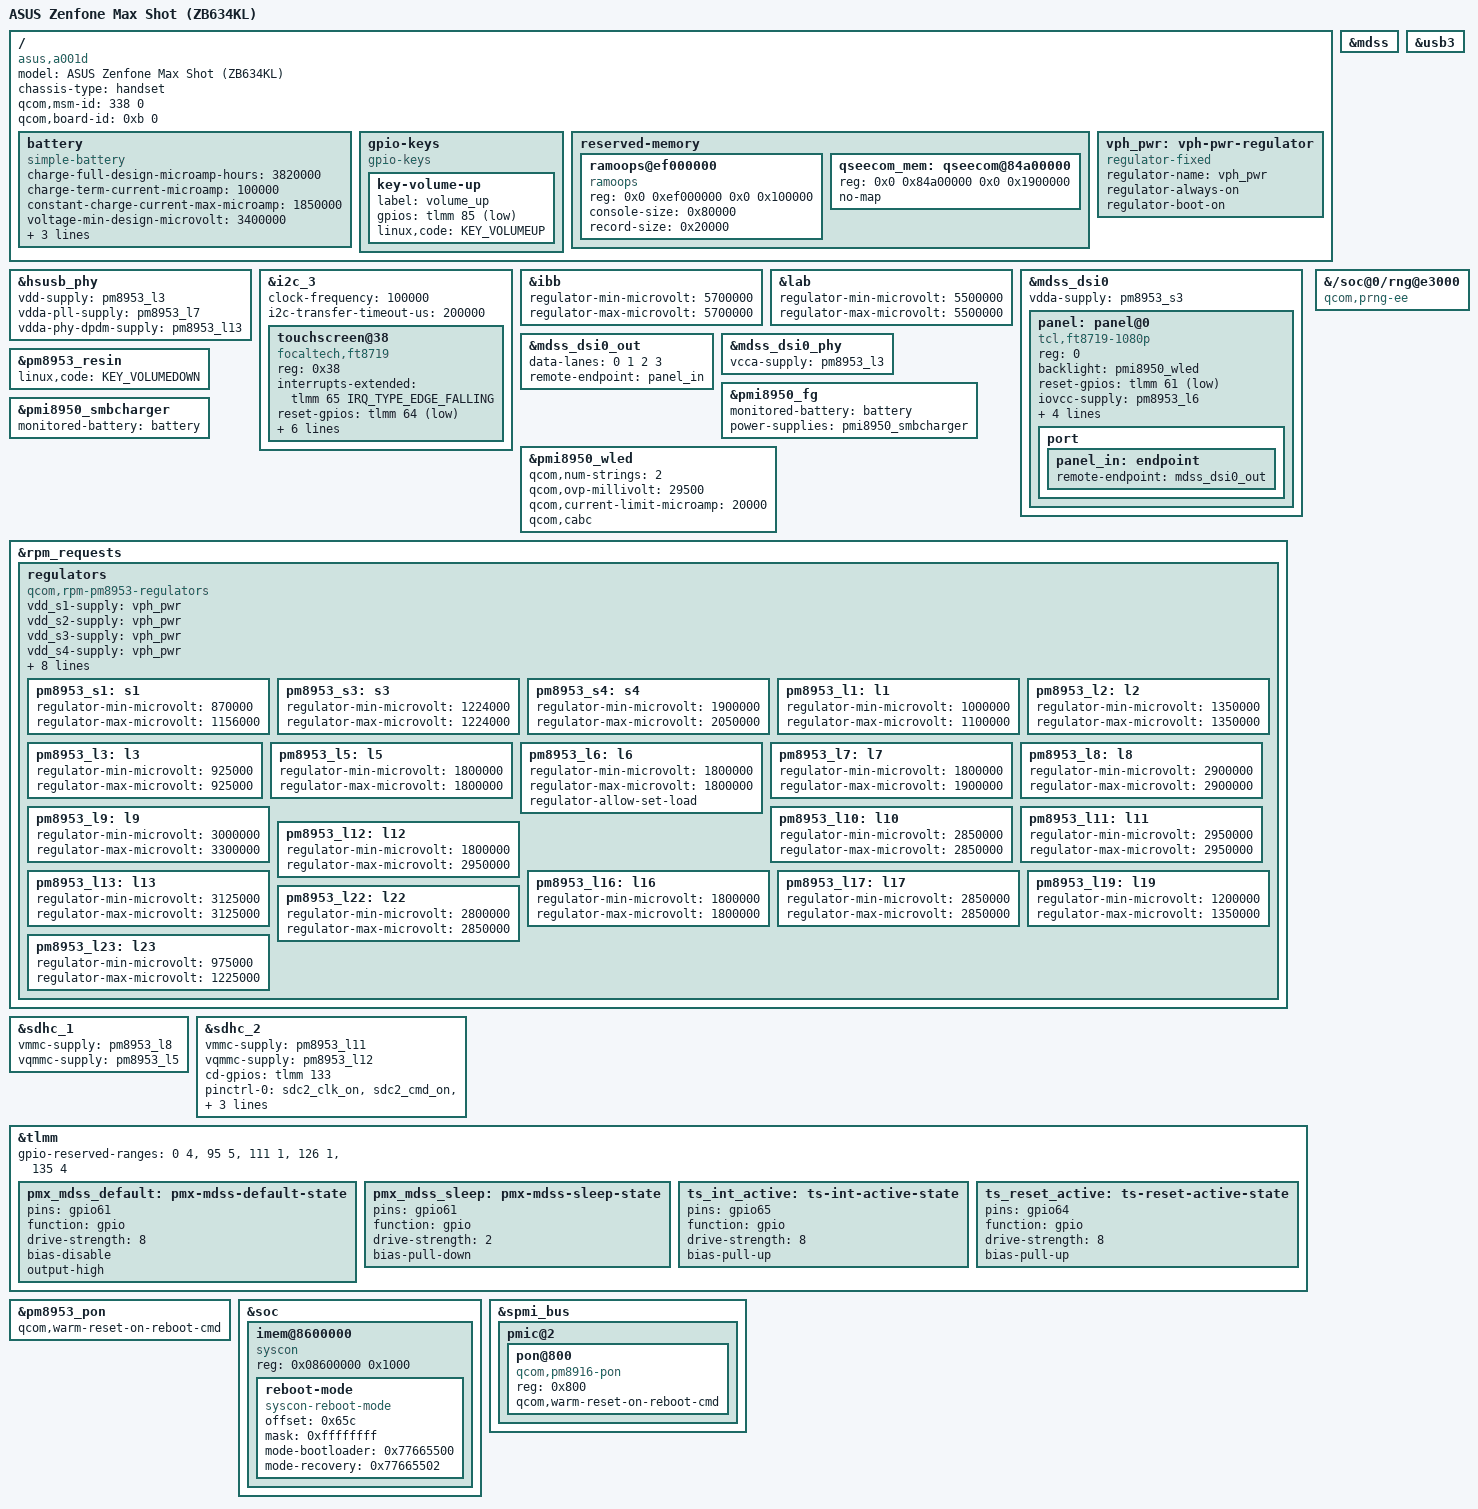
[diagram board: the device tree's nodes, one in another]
// SPDX-License-Identifier: BSD-3-Clause
/*
 * ASUS Zenfone Max Shot / Max Plus M2 (ZB634KL, ASUS_A001D).
 * Regulator ranges, reserved memory and display wiring come from the stock
 * 3.18 DTB. msm-id and board-id must match it so the stock LK selects this DTB.
 */
/dts-v1/;

#include "sdm450.dtsi"
#include "pm8953.dtsi"
#include "pmi8950.dtsi"

/delete-node/ &qseecom_mem;

/ {
	model = "ASUS Zenfone Max Shot (ZB634KL)";
	compatible = "asus,a001d", "qcom,sdm450";
	chassis-type = "handset";
	qcom,msm-id = <338 0>;
	qcom,board-id = <0xb 0>;

	/*
	 * 4.35 V cell, same float voltage, termination and charge current as
	 * stock. Stock JEITA thresholds: soft 10/45 C, hard 0/55 C. The charger
	 * enforces them in hardware, as on stock and on the 4.9 recovery.
	 */
	battery: battery {
		compatible = "simple-battery";

		charge-full-design-microamp-hours = <3820000>;
		charge-term-current-microamp = <100000>;
		constant-charge-current-max-microamp = <1850000>;
		voltage-min-design-microvolt = <3400000>;
		voltage-max-design-microvolt = <4350000>;
		alert-celsius = <10 45>;
		operating-range-celsius = <0 55>;
	};

	gpio-keys {
		compatible = "gpio-keys";

		key-volume-up {
			label = "volume_up";
			gpios = <&tlmm 85 GPIO_ACTIVE_LOW>;
			linux,code = <KEY_VOLUMEUP>;
		};
	};

	reserved-memory {
		/*
		 * Stock other_ext_region is 0x84a00000-0x86800000. TrustZone protects it.
		 * smem and reserved@86400000 from msm8953.dtsi already cover the top part.
		 */
		ramoops@ef000000 {
			compatible = "ramoops";
			reg = <0x0 0xef000000 0x0 0x100000>;
			console-size = <0x80000>;
			record-size = <0x20000>;
		};

		qseecom_mem: qseecom@84a00000 {
			reg = <0x0 0x84a00000 0x0 0x1900000>;
			no-map;
		};
	};

	vph_pwr: vph-pwr-regulator {
		compatible = "regulator-fixed";
		regulator-name = "vph_pwr";
		regulator-always-on;
		regulator-boot-on;
	};
};

&hsusb_phy {
	vdd-supply = <&pm8953_l3>;
	vdda-pll-supply = <&pm8953_l7>;
	vdda-phy-dpdm-supply = <&pm8953_l13>;

	status = "okay";
};

&i2c_3 {
	/*
	 * Not the stock 400 kHz: there the FT8719 intermittently returns no touch points
	 * for seconds while it keeps raising interrupts, so the touch freezes.
	 */
	clock-frequency = <100000>;
	/*
	 * The first read after the touch controller resets never completes. The driver
	 * retries it, so don't wait the 5 s default, sized for a 128 KiB DMA transfer.
	 */
	i2c-transfer-timeout-us = <200000>;
	status = "okay";

	/* FT8719 TDDI. The mainline driver has no firmware write path. */
	touchscreen@38 {
		compatible = "focaltech,ft8719";
		reg = <0x38>;
		interrupts-extended = <&tlmm 65 IRQ_TYPE_EDGE_FALLING>;
		reset-gpios = <&tlmm 64 GPIO_ACTIVE_LOW>;
		panel = <&panel>;

		iovcc-supply = <&pm8953_l6>;
		vcc-supply = <&lab>;

		pinctrl-0 = <&ts_int_active &ts_reset_active>;
		pinctrl-names = "default";

		touchscreen-size-x = <1080>;
		touchscreen-size-y = <2280>;
	};
};

/* Stock panel rails: qcom,qpnp-ibb-init-lcd-voltage and qcom,qpnp-lab-init-lcd-voltage */
&ibb {
	regulator-min-microvolt = <5700000>;
	regulator-max-microvolt = <5700000>;
};

&lab {
	regulator-min-microvolt = <5500000>;
	regulator-max-microvolt = <5500000>;
};

&mdss {
	status = "okay";
};

&mdss_dsi0 {
	vdda-supply = <&pm8953_s3>;
	status = "okay";

	panel: panel@0 {
		compatible = "tcl,ft8719-1080p";
		reg = <0>;

		backlight = <&pmi8950_wled>;
		reset-gpios = <&tlmm 61 GPIO_ACTIVE_LOW>;

		iovcc-supply = <&pm8953_l6>;
		vsp-supply = <&lab>;
		vsn-supply = <&ibb>;

		pinctrl-0 = <&pmx_mdss_default &mdss_te_default>;
		pinctrl-1 = <&pmx_mdss_sleep &mdss_te_default>;
		pinctrl-names = "default", "sleep";

		port {
			panel_in: endpoint {
				remote-endpoint = <&mdss_dsi0_out>;
			};
		};
	};
};

&mdss_dsi0_out {
	data-lanes = <0 1 2 3>;
	remote-endpoint = <&panel_in>;
};

&mdss_dsi0_phy {
	vcca-supply = <&pm8953_l3>;
	status = "okay";
};

&pm8953_resin {
	linux,code = <KEY_VOLUMEDOWN>;
	status = "okay";
};

&pmi8950_fg {
	monitored-battery = <&battery>;
	power-supplies = <&pmi8950_smbcharger>;

	status = "okay";
};

&pmi8950_smbcharger {
	monitored-battery = <&battery>;

	status = "okay";
};

&pmi8950_wled {
	qcom,num-strings = <2>;
	qcom,ovp-millivolt = <29500>;
	qcom,current-limit-microamp = <20000>;
	qcom,cabc;

	status = "okay";
};

&rpm_requests {
	regulators {
		compatible = "qcom,rpm-pm8953-regulators";

		vdd_s1-supply = <&vph_pwr>;
		vdd_s2-supply = <&vph_pwr>;
		vdd_s3-supply = <&vph_pwr>;
		vdd_s4-supply = <&vph_pwr>;
		vdd_s5-supply = <&vph_pwr>;
		vdd_s6-supply = <&vph_pwr>;
		vdd_s7-supply = <&vph_pwr>;
		vdd_l1-supply = <&pm8953_s3>;
		vdd_l2_l3-supply = <&pm8953_s3>;
		vdd_l4_l5_l6_l7_l16_l19-supply = <&pm8953_s4>;
		vdd_l8_l11_l12_l13_l14_l15-supply = <&vph_pwr>;
		vdd_l9_l10_l17_l18_l22-supply = <&vph_pwr>;

		pm8953_s1: s1 {
			regulator-min-microvolt = <870000>;
			regulator-max-microvolt = <1156000>;
		};

		/* Stock asks for 1.225 V; 1.224 V is the nearest step the driver accepts. */
		pm8953_s3: s3 {
			regulator-min-microvolt = <1224000>;
			regulator-max-microvolt = <1224000>;
		};

		pm8953_s4: s4 {
			regulator-min-microvolt = <1900000>;
			regulator-max-microvolt = <2050000>;
		};

		pm8953_l1: l1 {
			regulator-min-microvolt = <1000000>;
			regulator-max-microvolt = <1100000>;
		};

		pm8953_l2: l2 {
			regulator-min-microvolt = <1350000>;
			regulator-max-microvolt = <1350000>;
		};

		pm8953_l3: l3 {
			regulator-min-microvolt = <925000>;
			regulator-max-microvolt = <925000>;
		};

		pm8953_l5: l5 {
			regulator-min-microvolt = <1800000>;
			regulator-max-microvolt = <1800000>;
		};

		pm8953_l6: l6 {
			regulator-min-microvolt = <1800000>;
			regulator-max-microvolt = <1800000>;
			regulator-allow-set-load;
		};

		pm8953_l7: l7 {
			regulator-min-microvolt = <1800000>;
			regulator-max-microvolt = <1900000>;
		};

		pm8953_l8: l8 {
			regulator-min-microvolt = <2900000>;
			regulator-max-microvolt = <2900000>;
		};

		pm8953_l9: l9 {
			regulator-min-microvolt = <3000000>;
			regulator-max-microvolt = <3300000>;
		};

		pm8953_l10: l10 {
			regulator-min-microvolt = <2850000>;
			regulator-max-microvolt = <2850000>;
		};

		pm8953_l11: l11 {
			regulator-min-microvolt = <2950000>;
			regulator-max-microvolt = <2950000>;
		};

		pm8953_l12: l12 {
			regulator-min-microvolt = <1800000>;
			regulator-max-microvolt = <2950000>;
		};

		pm8953_l13: l13 {
			regulator-min-microvolt = <3125000>;
			regulator-max-microvolt = <3125000>;
		};

		pm8953_l16: l16 {
			regulator-min-microvolt = <1800000>;
			regulator-max-microvolt = <1800000>;
		};

		pm8953_l17: l17 {
			regulator-min-microvolt = <2850000>;
			regulator-max-microvolt = <2850000>;
		};

		pm8953_l19: l19 {
			regulator-min-microvolt = <1200000>;
			regulator-max-microvolt = <1350000>;
		};

		pm8953_l22: l22 {
			regulator-min-microvolt = <2800000>;
			regulator-max-microvolt = <2850000>;
		};

		pm8953_l23: l23 {
			regulator-min-microvolt = <975000>;
			regulator-max-microvolt = <1225000>;
		};
	};
};

&sdhc_1 {
	vmmc-supply = <&pm8953_l8>;
	vqmmc-supply = <&pm8953_l5>;

	status = "okay";
};

&sdhc_2 {
	vmmc-supply = <&pm8953_l11>;
	vqmmc-supply = <&pm8953_l12>;
	cd-gpios = <&tlmm 133 GPIO_ACTIVE_HIGH>;

	pinctrl-names = "default", "sleep";
	pinctrl-0 = <&sdc2_clk_on &sdc2_cmd_on &sdc2_data_on &sdc2_cd_off>;
	pinctrl-1 = <&sdc2_clk_off &sdc2_cmd_off &sdc2_data_off &sdc2_cd_off>;

	status = "okay";
};

&tlmm {
	/* Union of the ranges other msm8953 phones reserve; A001D ones are not known yet. */
	gpio-reserved-ranges = <0 4>, <95 5>, <111 1>, <126 1>, <135 4>;

	pmx_mdss_default: pmx-mdss-default-state {
		pins = "gpio61";
		function = "gpio";
		drive-strength = <8>;
		bias-disable;
		output-high;
	};

	pmx_mdss_sleep: pmx-mdss-sleep-state {
		pins = "gpio61";
		function = "gpio";
		drive-strength = <2>;
		bias-pull-down;
	};

	ts_int_active: ts-int-active-state {
		pins = "gpio65";
		function = "gpio";
		drive-strength = <8>;
		bias-pull-up;
	};

	ts_reset_active: ts-reset-active-state {
		pins = "gpio64";
		function = "gpio";
		drive-strength = <8>;
		bias-pull-up;
	};
};

&usb3 {
	status = "okay";
};

&pm8953_pon {
	qcom,warm-reset-on-reboot-cmd;
};

&soc {
	/* The stock LK reads the restart reason here, not from the PMIC */
	imem@8600000 {
		compatible = "syscon", "simple-mfd";
		reg = <0x08600000 0x1000>;

		reboot-mode {
			compatible = "syscon-reboot-mode";
			offset = <0x65c>;
			mask = <0xffffffff>;
			mode-bootloader = <0x77665500>;
			mode-recovery = <0x77665502>;
		};
	};
};

&spmi_bus {
	pmic@2 {
		/* Its PS_HOLD type defaults to shutdown, which would lose IMEM on a warm reset */
		pon@800 {
			compatible = "qcom,pm8916-pon";
			reg = <0x800>;
			qcom,warm-reset-on-reboot-cmd;
		};
	};
};

/* The secure world owns the PRNG setup here: the stock DT has qcom,no-qrng-config */
&{/soc@0/rng@e3000} {
	compatible = "qcom,prng-ee";
};
